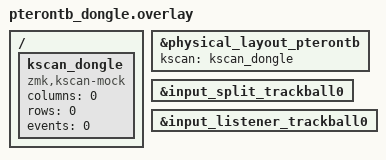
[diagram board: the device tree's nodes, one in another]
#include "pterontb.dtsi"

/ {
    kscan_dongle: kscan_dongle {
        compatible = "zmk,kscan-mock";
        columns = <0>;
        rows = <0>;
        events = <0>;
    };
};

&physical_layout_pterontb {
    kscan = <&kscan_dongle>;
};
// == Input devices ==
// Input devices on peripheral parts
// Enabling input listeners and input-split to receive input events from peripherals
&input_split_trackball0 { status = "okay"; };
&input_listener_trackball0 { status = "okay"; };
